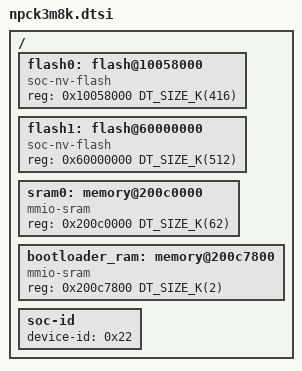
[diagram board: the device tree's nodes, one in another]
/*
 * Copyright (c) 2025 Nuvoton Technology Corporation.
 *
 * SPDX-License-Identifier: Apache-2.0
 */

#include <mem.h>
#include "npck/npck3.dtsi"

/ {
	flash0: flash@10058000 {
		compatible = "soc-nv-flash";
		reg = <0x10058000 DT_SIZE_K(416)>;
		ranges = <0 0x10058000 DT_SIZE_K(416)>;
		#address-cells = <1>;
		#size-cells = <1>;
	};

	flash1: flash@60000000 {
		compatible = "soc-nv-flash";
		reg = <0x60000000 DT_SIZE_K(512)>;
		ranges = <0 0x60000000 DT_SIZE_K(512)>;
		#address-cells = <1>;
		#size-cells = <1>;
	};

	sram0: memory@200c0000 {
		compatible = "mmio-sram";
		reg = <0x200c0000 DT_SIZE_K(62)>;
	};

	/* RAM space used by Booter */
	bootloader_ram: memory@200c7800 {
		compatible = "mmio-sram";
		reg = <0x200c7800 DT_SIZE_K(2)>;
	};

	soc-id {
		device-id = <0x22>;
	};
};
